# STM32F101 register map
File version: 1.2
CPU: CM3 r1p1, little endian, no MPU, no FPU, 4 interrupt priority bits
Registers are 32-bit, read-write, reset 0x0 unless marked. A register's access mark holds for its fields unless they carry their own. Offsets are from the block's base; [hi:lo] are bit positions; {n}, {i} and the like mark numbered series; 'fields as' and 'values as' point back to an identical list.

## AFIO — Alternate function I/O
Base 0x40010000
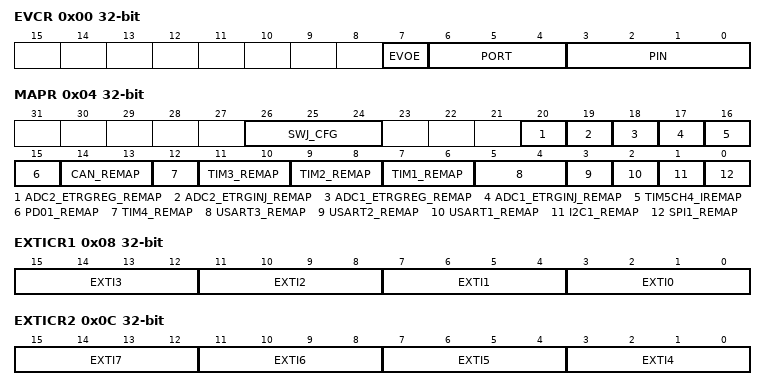
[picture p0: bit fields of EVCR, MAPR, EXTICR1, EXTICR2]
0x00 EVCR — Event Control Register (AFIO_EVCR)
  [7] EVOE — Event Output Enable
  [6:4] PORT — Port selection
  [3:0] PIN — Pin selection
0x04 MAPR access per field — AF remap and debug I/O configuration register (AFIO_MAPR)
  [26:24] SWJ_CFG wo — Serial wire JTAG configuration
  [20] ADC2_ETRGREG_REMAP rw — ADC 2 external trigger regular conversion remapping
  [19] ADC2_ETRGINJ_REMAP rw — ADC 2 external trigger injected conversion remapping
  [18] ADC1_ETRGREG_REMAP rw — ADC 1 external trigger regular conversion remapping
  [17] ADC1_ETRGINJ_REMAP rw — ADC 1 External trigger injected conversion remapping
  [16] TIM5CH4_IREMAP rw — Set and cleared by software
  [15] PD01_REMAP rw — Port D0/Port D1 mapping on OSCIN/OSCOUT
  [14:13] CAN_REMAP rw — CAN1 remapping
  [12] TIM4_REMAP rw — TIM4 remapping
  [11:10] TIM3_REMAP rw — TIM3 remapping
  [9:8] TIM2_REMAP rw — TIM2 remapping
  [7:6] TIM1_REMAP rw — TIM1 remapping
  [5:4] USART3_REMAP rw — USART3 remapping
  [3] USART2_REMAP rw — USART2 remapping
  [2] USART1_REMAP rw — USART1 remapping
  [1] I2C1_REMAP rw — I2C1 remapping
  [0] SPI1_REMAP rw — SPI1 remapping
0x08 EXTICR1 — External interrupt configuration register 1 (AFIO_EXTICR1)
  [4n+3:4n] EXTI{n} (n=0..3) — EXTI{n} configuration
0x0C EXTICR2 — External interrupt configuration register 2 (AFIO_EXTICR2)
  [4n-13:4n-16] EXTI{n} (n=4..7) — EXTI{n} configuration
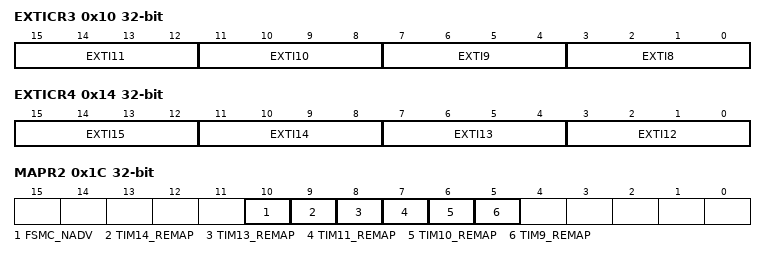
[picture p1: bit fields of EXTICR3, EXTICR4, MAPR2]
0x10 EXTICR3 — External interrupt configuration register 3 (AFIO_EXTICR3)
  [4n-29:4n-32] EXTI{n} (n=8..11) — EXTI{n} configuration
0x14 EXTICR4 — External interrupt configuration register 4 (AFIO_EXTICR4)
  [4n-45:4n-48] EXTI{n} (n=12..15) — EXTI{n} configuration
0x1C MAPR2 — AF remap and debug I/O configuration register
  [10] FSMC_NADV — NADV connect/disconnect
  [9] TIM14_REMAP — TIM14 remapping
  [8] TIM13_REMAP — TIM13 remapping
  [7] TIM11_REMAP — TIM11 remapping
  [6] TIM10_REMAP — TIM10 remapping
  [5] TIM9_REMAP — TIM9 remapping

## EXTI
Base 0x40010400
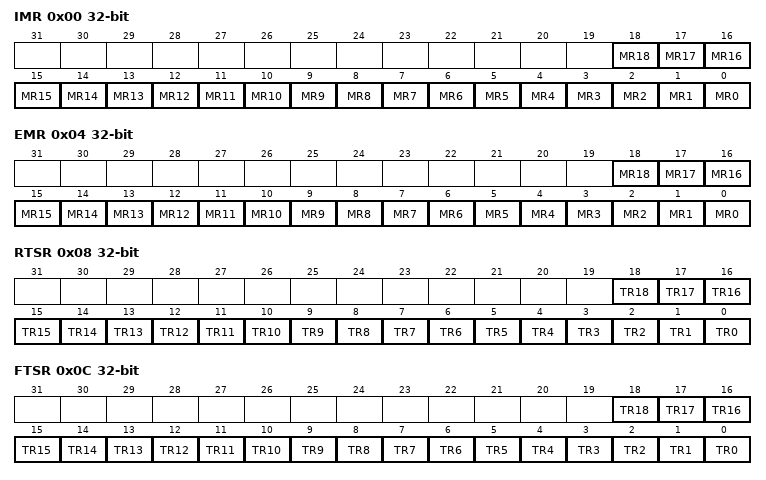
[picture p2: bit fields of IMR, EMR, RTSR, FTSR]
0x00 IMR — Interrupt mask register (EXTI_IMR)
  [n] MR{n} (n=0..18) — Interrupt Mask on line {n}
0x04 EMR — Event mask register (EXTI_EMR)
  [n] MR{n} (n=0..18) — Event Mask on line {n}
0x08 RTSR — Rising Trigger selection register (EXTI_RTSR)
  [n] TR{n} (n=0..18) — Rising trigger event configuration of line {n}
0x0C FTSR — Falling Trigger selection register (EXTI_FTSR)
  [n] TR{n} (n=0..18) — Falling trigger event configuration of line {n}
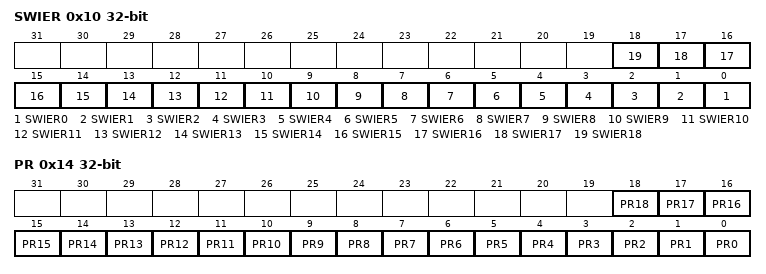
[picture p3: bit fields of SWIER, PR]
0x10 SWIER — Software interrupt event register (EXTI_SWIER)
  [n] SWIER{n} (n=0..18) — Software Interrupt on line {n}
0x14 PR — Pending register (EXTI_PR)
  [n] PR{n} (n=0..18) — Pending bit {n}

## DMA1 — DMA controller
Base 0x40020000
Same registers: DMA2 0x40020400
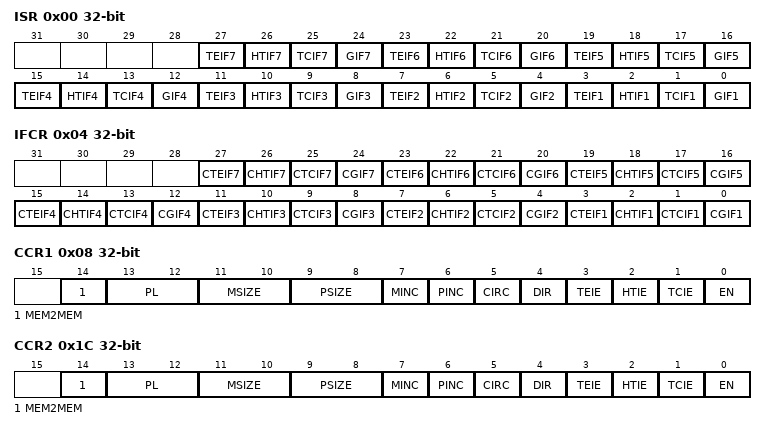
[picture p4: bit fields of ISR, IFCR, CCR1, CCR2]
0x00 ISR ro — DMA interrupt status register (DMA_ISR)
  [4n-1] TEIF{n} (n=1..7) — Channel {n} Transfer Error flag
  [4n-2] HTIF{n} (n=1..7) — Channel {n} Half Transfer Complete flag
  [4n-3] TCIF{n} (n=1..7) — Channel {n} Transfer Complete flag
  [4n-4] GIF{n} (n=1..7) — Channel {n} Global interrupt flag
0x04 IFCR wo — DMA interrupt flag clear register (DMA_IFCR)
  [4n-1] CTEIF{n} (n=1..7) — Channel {n} Transfer Error clear
  [4n-2] CHTIF{n} (n=1..7) — Channel {n} Half Transfer clear
  [4n-3] CTCIF{n} (n=1..7) — Channel {n} Transfer Complete clear
  [4n-4] CGIF{n} (n=1..7) — Channel {n} Global interrupt clear
0x08 CCR1 — DMA channel configuration register (DMA_CCR)
  [14] MEM2MEM — Memory to memory mode
  [13:12] PL — Channel Priority level
  [11:10] MSIZE — Memory size
  [9:8] PSIZE — Peripheral size
  [7] MINC — Memory increment mode
  [6] PINC — Peripheral increment mode
  [5] CIRC — Circular mode
  [4] DIR — Data transfer direction
  [3] TEIE — Transfer error interrupt enable
  [2] HTIE — Half Transfer interrupt enable
  [1] TCIE — Transfer complete interrupt enable
  [0] EN — Channel enable
0x0C CNDTR1 — DMA channel 1 number of data register
  [15:0] NDT — Number of data to transfer
0x10 CPAR1 — DMA channel 1 peripheral address register
  [31:0] PA — Peripheral address
{0x0+0x14*i} CMAR{i} (i=1..7) — DMA channel {i} memory address register
  [31:0] MA — Memory address
0x1C CCR2 — DMA channel configuration register (DMA_CCR)
  fields as CCR1
0x20 CNDTR2 — DMA channel 2 number of data register
  [15:0] NDT — Number of data to transfer
0x24 CPAR2 — DMA channel 2 peripheral address register
  [31:0] PA — Peripheral address
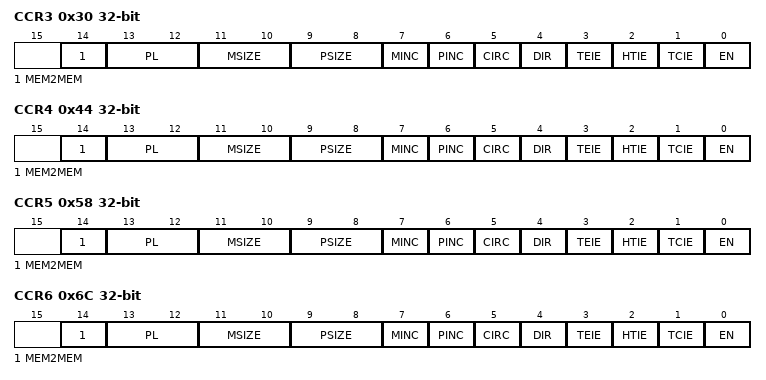
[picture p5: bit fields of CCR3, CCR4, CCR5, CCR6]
0x30 CCR3 — DMA channel configuration register (DMA_CCR)
  fields as CCR1
0x34 CNDTR3 — DMA channel 3 number of data register
  [15:0] NDT — Number of data to transfer
0x38 CPAR3 — DMA channel 3 peripheral address register
  [31:0] PA — Peripheral address
0x44 CCR4 — DMA channel configuration register (DMA_CCR)
  fields as CCR1
0x48 CNDTR4 — DMA channel 4 number of data register
  [15:0] NDT — Number of data to transfer
0x4C CPAR4 — DMA channel 4 peripheral address register
  [31:0] PA — Peripheral address
0x58 CCR5 — DMA channel configuration register (DMA_CCR)
  fields as CCR1
0x5C CNDTR5 — DMA channel 5 number of data register
  [15:0] NDT — Number of data to transfer
0x60 CPAR5 — DMA channel 5 peripheral address register
  [31:0] PA — Peripheral address
0x6C CCR6 — DMA channel configuration register (DMA_CCR)
  fields as CCR1
0x70 CNDTR6 — DMA channel 6 number of data register
  [15:0] NDT — Number of data to transfer
0x74 CPAR6 — DMA channel 6 peripheral address register
  [31:0] PA — Peripheral address
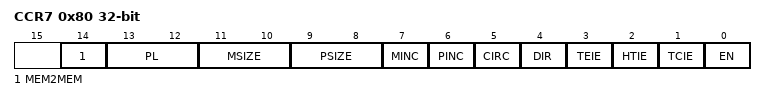
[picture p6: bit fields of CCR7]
0x80 CCR7 — DMA channel configuration register (DMA_CCR)
  fields as CCR1
0x84 CNDTR7 — DMA channel 7 number of data register
  [15:0] NDT — Number of data to transfer
0x88 CPAR7 — DMA channel 7 peripheral address register
  [31:0] PA — Peripheral address
